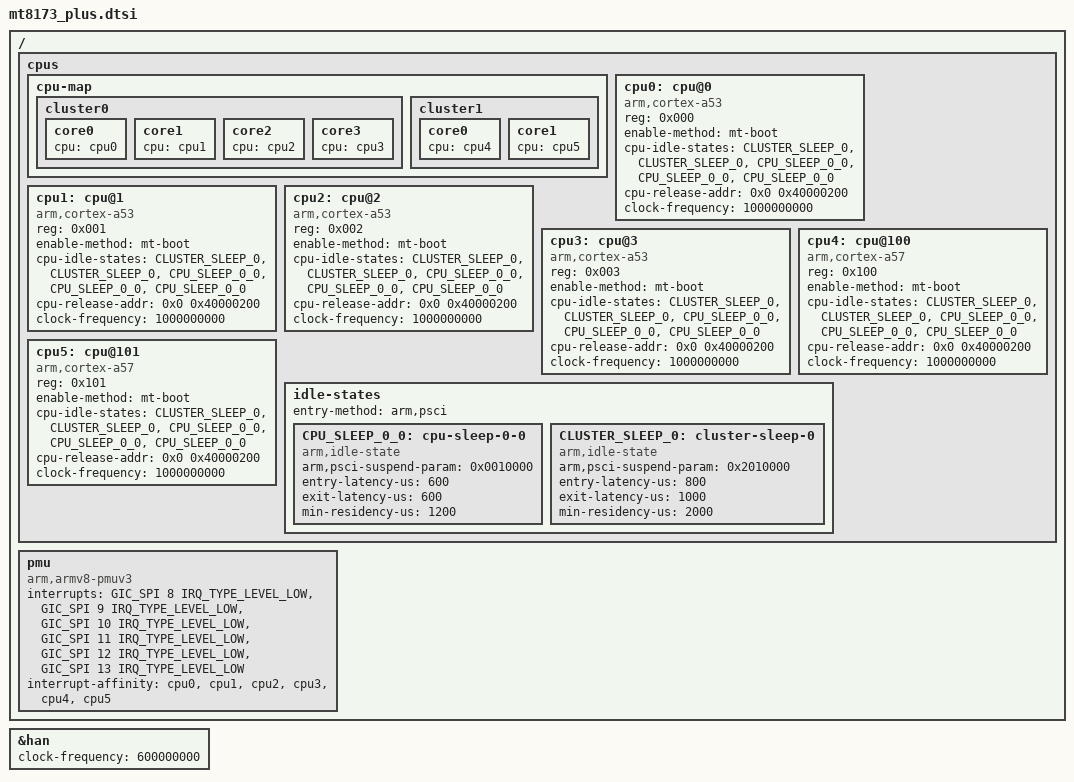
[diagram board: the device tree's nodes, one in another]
/*
 * Copyright (c) 2014 MediaTek Inc.
 * Author: Eddie Huang <eddie.huang@mediatek.com>
 *
 * This program is free software; you can redistribute it and/or modify
 * it under the terms of the GNU General Public License version 2 as
 * published by the Free Software Foundation.
 *
 * This program is distributed in the hope that it will be useful,
 * but WITHOUT ANY WARRANTY; without even the implied warranty of
 * MERCHANTABILITY or FITNESS FOR A PARTICULAR PURPOSE.  See the
 * GNU General Public License for more details.
 */

#include "mt8173.dtsi"

/ {
	cpus {
		#address-cells = <1>;
		#size-cells = <0>;

		cpu-map {
			cluster0 {
				core0 {
					cpu = <&cpu0>;
				};
				core1 {
					cpu = <&cpu1>;
				};
				core2 {
					cpu = <&cpu2>;
				};
				core3 {
					cpu = <&cpu3>;
				};
			};

			cluster1 {
				core0 {
					cpu = <&cpu4>;
				};
				core1 {
					cpu = <&cpu5>;
				};
			};
		};

		cpu0: cpu@0 {
			device_type = "cpu";
			compatible = "arm,cortex-a53";
			reg = <0x000>;
			enable-method = "mt-boot";
			cpu-idle-states = <&CLUSTER_SLEEP_0 &CLUSTER_SLEEP_0>,
					  <&CPU_SLEEP_0_0 &CPU_SLEEP_0_0 &CPU_SLEEP_0_0>;
			cpu-release-addr = <0x0 0x40000200>;
			clock-frequency = <1000000000>;
		};

		cpu1: cpu@1 {
			device_type = "cpu";
			compatible = "arm,cortex-a53";
			reg = <0x001>;
			enable-method = "mt-boot";
			cpu-idle-states = <&CLUSTER_SLEEP_0 &CLUSTER_SLEEP_0>,
					  <&CPU_SLEEP_0_0 &CPU_SLEEP_0_0 &CPU_SLEEP_0_0>;
			cpu-release-addr = <0x0 0x40000200>;
			clock-frequency = <1000000000>;
		};

		cpu2: cpu@2 {
			device_type = "cpu";
			compatible = "arm,cortex-a53";
			reg = <0x002>;
			enable-method = "mt-boot";
			cpu-idle-states = <&CLUSTER_SLEEP_0 &CLUSTER_SLEEP_0>,
					  <&CPU_SLEEP_0_0 &CPU_SLEEP_0_0 &CPU_SLEEP_0_0>;
			cpu-release-addr = <0x0 0x40000200>;
			clock-frequency = <1000000000>;
		};

		cpu3: cpu@3 {
			device_type = "cpu";
			compatible = "arm,cortex-a53";
			reg = <0x003>;
			enable-method = "mt-boot";
			cpu-idle-states = <&CLUSTER_SLEEP_0 &CLUSTER_SLEEP_0>,
					  <&CPU_SLEEP_0_0 &CPU_SLEEP_0_0 &CPU_SLEEP_0_0>;
			cpu-release-addr = <0x0 0x40000200>;
			clock-frequency = <1000000000>;
		};

		cpu4: cpu@100 {
			device_type = "cpu";
			compatible = "arm,cortex-a57";
			reg = <0x100>;
			enable-method = "mt-boot";
			cpu-idle-states = <&CLUSTER_SLEEP_0 &CLUSTER_SLEEP_0>,
					  <&CPU_SLEEP_0_0 &CPU_SLEEP_0_0 &CPU_SLEEP_0_0>;
			cpu-release-addr = <0x0 0x40000200>;
			clock-frequency = <1000000000>;
		};

		cpu5: cpu@101 {
			device_type = "cpu";
			compatible = "arm,cortex-a57";
			reg = <0x101>;
			enable-method = "mt-boot";
			cpu-idle-states = <&CLUSTER_SLEEP_0 &CLUSTER_SLEEP_0>,
					  <&CPU_SLEEP_0_0 &CPU_SLEEP_0_0 &CPU_SLEEP_0_0>;
			cpu-release-addr = <0x0 0x40000200>;
			clock-frequency = <1000000000>;
		};

		idle-states {
			entry-method = "arm,psci";

			CPU_SLEEP_0_0: cpu-sleep-0-0 {
				compatible = "arm,idle-state";
				arm,psci-suspend-param = <0x0010000>;
				entry-latency-us = <600>;
				exit-latency-us = <600>;
				min-residency-us = <1200>;
			};

			CLUSTER_SLEEP_0: cluster-sleep-0 {
				compatible = "arm,idle-state";
				arm,psci-suspend-param = <0x2010000>;
				entry-latency-us = <800>;
				exit-latency-us = <1000>;
				min-residency-us = <2000>;
			};
		};
	};

	pmu {
		compatible = "arm,armv8-pmuv3";
		interrupts = <GIC_SPI 8 IRQ_TYPE_LEVEL_LOW>,
			     <GIC_SPI 9 IRQ_TYPE_LEVEL_LOW>,
			     <GIC_SPI 10 IRQ_TYPE_LEVEL_LOW>,
			     <GIC_SPI 11 IRQ_TYPE_LEVEL_LOW>,
			     <GIC_SPI 12 IRQ_TYPE_LEVEL_LOW>,
			     <GIC_SPI 13 IRQ_TYPE_LEVEL_LOW>;
		interrupt-affinity = <&cpu0>,
				     <&cpu1>,
				     <&cpu2>,
				     <&cpu3>,
				     <&cpu4>,
				     <&cpu5>;
	};
};

&han {
	clock-frequency = <600000000>;
};
